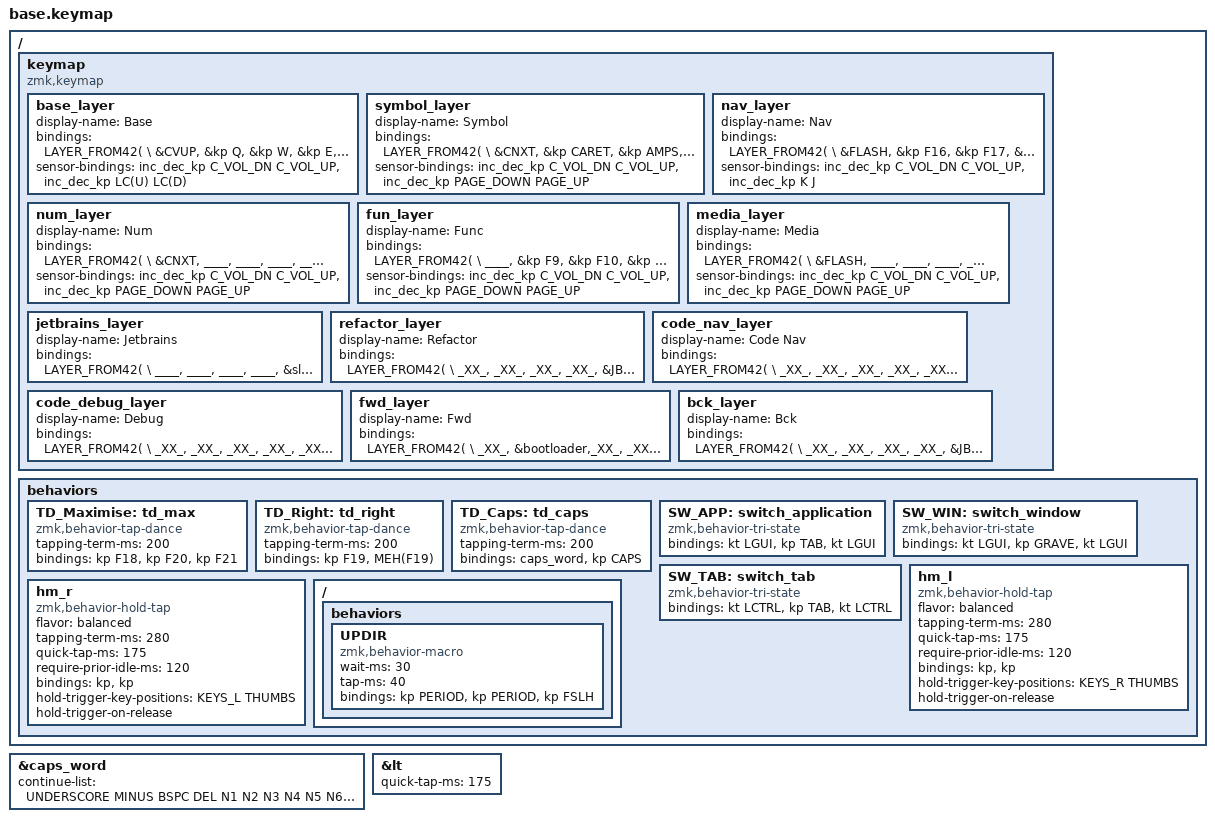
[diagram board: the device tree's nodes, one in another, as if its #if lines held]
/*
 * Copyright (c) 2020 The ZMK Contributors
 *
 * SPDX-License-Identifier: MIT
 */
 
#ifndef LAYER_FROM42
#include "keypos_42keys.h"
#endif

#include <behaviors.dtsi>
#include <dt-bindings/zmk/keys.h>
#include <dt-bindings/zmk/bt.h>
#include "layer_names.h"
#include "kp_mac.h"
#include "kp_media.h"
#include "kp_jetbrains.h"
#include "combos.h"

#define _XX_ &none
#define ____ &trans

&caps_word {
    continue-list = <UNDERSCORE MINUS BSPC DEL N1 N2 N3 N4 N5 N6 N7 N8 N9 N0>;
};

&lt {
   quick-tap-ms = <175>;                // repeat on tap-into-hold
};

/ {
        keymap {
                compatible = "zmk,keymap";

                base_layer {
                        display-name = "Base";
// -----------------------------------------------------------------------------------------
// |      |  Q  |  W  |  E  |  R  |  T  |   |  Y  |  U   |  I  |  O  |  P  |      |
// |      |  A  |  S  |  D  |  F  |  G  |   |  H  |  J   |  K  |  L  |  ;  |      |
// |      |  Z  |  X  |  C  |  V  |  B  |   |  N  |  M   |  ,  |  .  |  /  |      |
//                    | TAB | RET | ESC |   | BSP | SPC  | DEL |
                        bindings = <LAYER_FROM42(   \
&CVUP, &kp Q,   &kp W,  &kp E,          &kp R,        &kp T,        /**/  &kp Y,         &kp U,        &kp I,      &kp O,    &kp P,     &MC_ZIN,
&CPP,  &MC_A,   &MC_S,  &MC_D,          &MC_F,        &kp G,        /**/  &kp H,         &MC_J,        &MC_K,      &MC_L,    &MC_SEMI,  &MC_PSC,
&CVDN, &kp Z,   &kp X,  &kp C,          &lt FWD V,    &kp B,        /**/  &kp N,         &lt BCK M,    &kp COMMA,  &kp DOT,  &kp FSLH,  &MC_ZOT,
                        &lt MEDIA TAB,  &lt NUM RET,  &lt NAV ESC,  /**/  &lt FUN BSPC,  &lt SYM SPC,  &kp DEL
                        )>;

                        #ifdef corneroll
                         sensor-bindings = <
                                &inc_dec_kp C_VOL_DN C_VOL_UP
                                &inc_dec_kp LC(U) LC(D)
                        >;
                        #endif

                };

                symbol_layer {
                        display-name="Symbol";

// -----------------------------------------------------------------------------------------
// | >>  | HAT |  &  |  #  |  ~  |  (  |   |  )  |     |     |     |     |      |
// |     |  `  |  |  |  !  |   ' |  {  |   |  }  |     |     |     |     |      |
// | <<  |BSLH |  @  |  $  |  £  |  [  |   |  ]  |     |     |     |     |      |
//                   |  _  |  -  |  "  |   |     |     |     |
                        bindings = <LAYER_FROM42(   \
&CNXT,  &kp CARET,   &kp AMPS, &kp HASH,  &MC_TLD,   &kp LPAR, /**/    &kp RPAR, ____,   ____,   ____,   ____,   ____,
&STOP,  &kp GRAVE,   &MC_PPE,  &kp EXCL,  &kp SQT,   &kp LBRC, /**/    &kp RBRC, ____,   ____,   ____,   ____,   ____,
&CPRV,  &kp BSLH,    &MC_AT,   &kp DLLR,  &MC_PND,   &kp LBKT, /**/    &kp RBKT, ____,   ____,   ____,   ____,   ____,
                               &kp UNDER, &kp MINUS, &MC_DQT,  /**/    ____,     ____,   ____
                        )>;

                        #ifdef corneroll
                         sensor-bindings = <
                                &inc_dec_kp C_VOL_DN C_VOL_UP
                                &inc_dec_kp PAGE_DOWN PAGE_UP
                        >;
                        #endif

                };

                nav_layer {
                        display-name="Nav";
// -----------------------------------------------------------------------------------------
// |flash | F16 | F17 | F18 | F19 | F20 |   |SwApp| Pwd  | Nwd | PGUP|     |      |
// |      |UNDO | CUT | COPY|PASTE|CAPS |   |  <  |  v   |  ^  |  >  |     |      |
// |      |     |     |     |     |     |   |SwWin| Home | End | PgDN|     |      |
//                    |     |     |     |   |     | Spot |     |
                        bindings = <LAYER_FROM42(   \
&FLASH,   &kp F16, &kp F17, &TD_Maximise, &TD_Right, ____,    /**/    &SW_APP,       &MC_PWD,     &MC_NWD,  &kp PG_UP,  ____,  ____,
____,    &MC_UND, &MC_CUT, &MC_CPY,      &MC_PST,   &TD_Caps, /**/    &kp LEFT,      &kp DOWN,    &kp UP,   &kp RIGHT,  ____,  ____,
____,    ____,      ____,    ____,       ____,      ____,     /**/    &SW_TAB,       &MC_HME,     &MC_END,  &kp PG_DN,  ____,  ____,
                             ____,       ____,      ____,     /**/    &kp LA(BSPC),  &kp LG(SPC), ____
                        )>;

                        #ifdef corneroll
                         sensor-bindings = <
                                &inc_dec_kp C_VOL_DN C_VOL_UP
                                &inc_dec_kp K J
                        >;
                        #endif

                };

                num_layer {
                        display-name="Num";
// -----------------------------------------------------------------------------------------
// |      |     |     |     |     |     |   |  *  |  7   |  8  |  9  |     |      |
// |      | CTRL| ALT | GUI | SHFT|     |   |  +  |  4   |  5  |  6  |  /  |      |
// |      |     |     |     |     |     |   |  -  |  1   |  2  |  3  |  %  |      |
//                    |     |     |     |   |  =  |  0   |  .  |
                        bindings = <LAYER_FROM42(   \
&CNXT,   ____,      ____,      ____,      ____,       ____,     /**/    &kp STAR,  &kp N7,  &kp N8,  &kp N9,  ____,      ____,
____,    &kp LCTRL, &kp LALT,  &kp LGUI,  &kp LSHFT,  ____,     /**/    &kp PLUS,  &kp N4,  &kp N5,  &kp N6,  &kp FSLH,  ____,
&CPRV,   ____,      ____,      ____,      ____,       ____,     /**/    &kp MINUS, &kp N1,  &kp N2,  &kp N3,  &kp PRCNT, ____,
                               ____,      ____,       ____,     /**/    &kp EQUAL, &kp N0,  &kp DOT
                        )>;

                        #ifdef corneroll
                         sensor-bindings = <
                                &inc_dec_kp C_VOL_DN C_VOL_UP
                                &inc_dec_kp PAGE_DOWN PAGE_UP
                        >;
                        #endif

                };

                fun_layer {
                        display-name="Func";
// -----------------------------------------------------------------------------------------
// |      |     | F9  | F10 | F11 | F12 |   |     |      |     |     |     | FLASH|
// |      |     | F5  |  F6 |  F7 |  F8 |   |     |      |     |     |     |      |
// |      |     | F1  |  F2 |  F3 |  F4 |   |     |      |     |     |     |      |
//                    |     |     |     |   |     |      |     |
                        bindings = <LAYER_FROM42(   \
____,   &kp F9,  &kp F10, &kp F11, &kp F12, ____,   /**/   ____,    ____,      ____,      ____,     ____,     &FLASH,
____,   &kp F5,  &kp F6,  &kp F7,  &kp F8,  ____,   /**/   ____,    &kp LSHFT, &kp LCTRL, &kp LALT, &kp LGUI, ____,
____,   &kp F1,  &kp F2,  &kp F3,  &kp F4,  ____,   /**/   ____,    ____,      ____,      ____,     ____,     ____,
                          ____,    ____,    ____,   /**/   ____,    ____,      ____
                        )>;

                        #ifdef corneroll
                         sensor-bindings = <
                                &inc_dec_kp C_VOL_DN C_VOL_UP
                                &inc_dec_kp PAGE_DOWN PAGE_UP
                        >;
                        #endif

                };

                media_layer {
                        display-name="Media";
// -----------------------------------------------------------------------------------------
// | FLASH|     |     |     |     |     |   |     |      |     |     |     |      |
// |      |     |     |     |     |     |   |     |      |     |     |     |      |
// |BTCLR | BT0 | BT1 | BT2 |     |     |   |     |      |     |     |     |      |
//                    |     |     |     |   |     |      |     |
                        bindings = <LAYER_FROM42(   \
&FLASH, ____,   ____,   ____,   ____,   ____,   /**/    ____, ____,  ____,  ____,  ____,  ____,
____,   ____,   ____,   ____,   ____,   ____,   /**/    ____, ____,  ____,  ____,  ____,  ____,
&BTCLR, &BT0,   &BT1,   &BT2,   ____,   ____,   /**/    ____, ____,  ____,  ____,  ____,  ____,
                        ____,   ____,   ____,   /**/    ____, ____,  ____
                        )>;

                        #ifdef corneroll
                         sensor-bindings = <
                                &inc_dec_kp C_VOL_DN C_VOL_UP
                                &inc_dec_kp PAGE_DOWN PAGE_UP
                        >;
                        #endif
                };


                jetbrains_layer {
                        display-name="Jetbrains";
// -----------------------------------------------------------------------------------------
// |      |     |     |     | REF |     |   |       |      |     |     |     |      |
// |      |     |     | DBG |     |     |   |       |      |     |     |     |      |
// |      |     |     |     |     |     |   |CODENAV|      |     |     |     |      |
//                    |     |     |BASE |   |       |      |     |
                        bindings = <LAYER_FROM42(   \
____,    ____,    ____,    ____,    &sl REF , ____,     /**/    ____,         ____,   ____,  ____,    ____,    ____,
____,    ____,    ____,    &to DBG , ____,    ____,     /**/    ____,         ____,   ____,  ____,    ____,    ____,
____,    ____,    ____,    ____,    ____,    ____,     /**/    &sl CODENAV ,  ____,   ____,  ____,    ____,    ____,
                           ____,    ____,    &to BASE , /**/    ____,         ____,   ____
                        )>;
                };


                refactor_layer {
                        display-name="Refactor";

                        bindings = <LAYER_FROM42(   \
_XX_,    _XX_,    _XX_,    _XX_,    &JB_RR,  &JB_RT,  /**/    _XX_,    _XX_,    &JB_RN,  _XX_,    &JB_RP,  _XX_,
_XX_,    _XX_,    &JB_RS,  &JB_RD,  &JB_RF,  _XX_,    /**/    _XX_,    _XX_,    _XX_,    _XX_,    _XX_,    _XX_,
_XX_,    _XX_,    _XX_,    &JB_RC,  &JB_RV,  _XX_,    /**/    &JB_RN,  &JB_RM,  _XX_,    _XX_,    _XX_,    _XX_,
                           _XX_,    _XX_,    &to BASE , /**/    _XX_,    _XX_,    _XX_
                        )>;
                };


                code_nav_layer {
                        display-name="Code Nav";
                        bindings = <LAYER_FROM42(   \
_XX_,    _XX_,    _XX_,    _XX_,    _XX_,    &JB_NT,  /**/    _XX_,  &JB_NU,  _XX_,    _XX_,    _XX_,    _XX_,
_XX_,    _XX_,    _XX_,    &JB_ND,  _XX_,    _XX_,    /**/    _XX_,   _XX_,   _XX_,    _XX_,    _XX_,    _XX_,
_XX_,    _XX_,    _XX_,    _XX_,    _XX_,    _XX_,    /**/    _XX_,   _XX_,   _XX_,    _XX_,    _XX_,    _XX_,
                           _XX_,    _XX_,    &to BASE , /**/    _XX_,  &JB_NM,   _XX_
                        )>;
                };


                code_debug_layer {
                        display-name="Debug";
                        bindings = <LAYER_FROM42(   \
_XX_,    _XX_,    _XX_,    _XX_,    _XX_,    _XX_,    /**/    _XX_,     _XX_,    _XX_,    _XX_,    _XX_,    _XX_,
_XX_,    _XX_,    _XX_,    _XX_,    _XX_,    _XX_,    /**/    &JB_DR,   &JB_DI,  &JB_DU,  &JB_DO,  _XX_,    _XX_,
_XX_,    _XX_,    _XX_,    _XX_,    _XX_,    &JB_DB,  /**/    _XX_,     _XX_,    _XX_,    _XX_,    _XX_,    _XX_,
                           _XX_,    _XX_,    &to BASE ,/**/    &JB_BB,   _XX_,    _XX_
                        )>;
                };


                fwd_layer {
                        display-name="Fwd";
                        bindings = <LAYER_FROM42(   \
_XX_, &bootloader,_XX_,    _XX_,    _XX_,    _XX_,    /**/    _XX_,         &JB_NU,         _XX_,    _XX_,    _XX_,    _XX_,
_XX_,    _XX_,    _XX_,    _XX_,    _XX_,    _XX_,    /**/    _XX_,         _XX_,           _XX_,    _XX_,    _XX_,    _XX_,
_XX_,    _XX_,    _XX_,    _XX_,    _XX_,    _XX_,    /**/    _XX_,         &kp LG(RBKT),   _XX_,    _XX_,    _XX_,    _XX_,
                           _XX_,    _XX_,    _XX_,    /**/    _XX_,         _XX_,           _XX_
                        )>;
                };


                bck_layer {
                        display-name="Bck";
                        bindings = <LAYER_FROM42(   \
_XX_,    _XX_,    _XX_,    _XX_,    &JB_RR,          _XX_,    /**/    _XX_,         _XX_,           _XX_,    _XX_,    &bootloader, _XX_,
_XX_,    _XX_,    _XX_,    _XX_,    _XX_,            _XX_,    /**/    _XX_,         _XX_,           _XX_,    _XX_,    _XX_,    _XX_,
_XX_,    _XX_,    _XX_,    _XX_,    &kp LG(LBKT),    _XX_,    /**/    _XX_,         _XX_,           _XX_,    _XX_,    _XX_,    _XX_,
                           _XX_,    _XX_,            _XX_,    /**/    _XX_,         _XX_,           _XX_
                        )>;
                };


//                 trans_layer {
//                         display-name="Trans";
// // -----------------------------------------------------------------------------------------
// // |      |     |     |     |     |     |   |     |      |     |     |     |      |
// // |      |     |     |     |     |     |   |     |      |     |     |     |      |
// // |      |     |     |     |     |     |   |     |      |     |     |     |      |
// //                    |     |     |     |   |     |      |     |
//                         bindings = <LAYER_FROM42(//    ____    ____    ____    ____    ____    ____    /**/    ____         ____           ____    ____    ____    ____
//    ____    ____    ____    ____    ____    ____    /**/    ____         ____           ____    ____    ____    ____
//    ____    ____    ____    ____    ____    ____    /**/    ____         ____           ____    ____    ____    ____
//                            ____    ____    ____    /**/    ____         ____           ____
//                         )>;
//                 };


        };
};

#define U_TAPPING_TERM 220

/ {
  behaviors {

    TD_Maximise: td_max {
        compatible = "zmk,behavior-tap-dance";
        #binding-cells = <0>;
        tapping-term-ms = <200>;
        bindings = <&kp F18>, <&kp F20>, <&kp F21>;
    };

    TD_Right: td_right {
        compatible = "zmk,behavior-tap-dance";
        #binding-cells = <0>;
        tapping-term-ms = <200>;
        bindings = <&kp F19>, <&MEH(F19)>;
    };

    TD_Caps: td_caps {
        compatible = "zmk,behavior-tap-dance";
        #binding-cells = <0>;
        tapping-term-ms = <200>;
        bindings = <&caps_word>, <&kp CAPS>;
    };

    SW_APP: switch_application {
      compatible = "zmk,behavior-tri-state";
      #binding-cells = <0>;
      bindings = <&kt LGUI>, <&kp TAB>, <&kt LGUI>;
    };

    SW_WIN: switch_window {
      compatible = "zmk,behavior-tri-state";
      #binding-cells = <0>;
      bindings = <&kt LGUI>, <&kp GRAVE>, <&kt LGUI>;
    };

    SW_TAB: switch_tab {
      compatible = "zmk,behavior-tri-state";
      #binding-cells = <0>;
      bindings = <&kt LCTRL>, <&kp TAB>, <&kt LCTRL>;
    };

    hm_l: hm_l {
        compatible = "zmk,behavior-hold-tap";
        #binding-cells = <2>;
        flavor = "balanced";
        tapping-term-ms = <280>;
        quick-tap-ms = <175>;                // repeat on tap-into-hold
        require-prior-idle-ms = <120>;
        bindings = <&kp>, <&kp>;
        hold-trigger-key-positions = <KEYS_R THUMBS>;
        hold-trigger-on-release;             // delay positional check until key-release
    };

    hm_r: hm_r {
        compatible = "zmk,behavior-hold-tap";
        #binding-cells = <2>;
        flavor = "balanced";
        tapping-term-ms = <280>;
        quick-tap-ms = <175>;                // repeat on tap-into-hold
        require-prior-idle-ms = <120>;
        bindings = <&kp>, <&kp>;
        hold-trigger-key-positions = <KEYS_L THUMBS>;
        hold-trigger-on-release;             // delay positional check until key-release
    };

    ZMK_MACRO(UPDIR,
        wait-ms = <30>;
        tap-ms = <40>;
        bindings = <&kp PERIOD &kp PERIOD &kp FSLH>;
    )

  };
};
